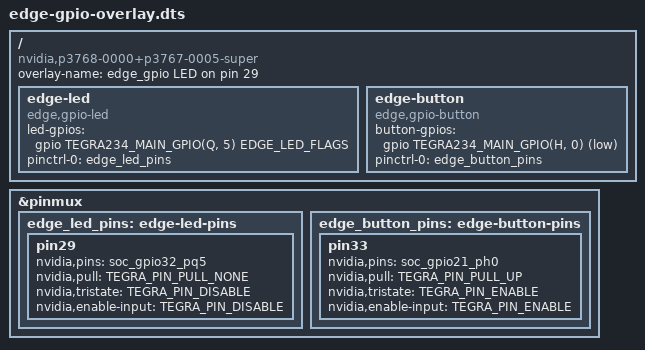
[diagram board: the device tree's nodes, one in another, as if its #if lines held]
// SPDX-License-Identifier: GPL-2.0
/*
 * Step 4: describe one LED on the 40-pin header so edge_gpio.ko can probe.
 *
 *   header pin 29 (GPIO01, SoC pad PQ.05) --[330R..1k]-->|-- pin 30 (GND)
 *
 * JP6 boots this pad tristated, so the node also carries a "default" pinctrl
 * state that turns the output buffer on; the platform core applies it right
 * before edge_gpio's probe().
 *
 * Built with cpp + dtc by dts/Makefile; -DEDGE_LED_ACTIVE_LOW builds the
 * variant for an LED wired from 3.3 V into the pin (lit when the pin is low).
 */
/dts-v1/;
/plugin/;

#include <dt-bindings/gpio/gpio.h>
#include <dt-bindings/gpio/tegra234-gpio.h>
#include <dt-bindings/pinctrl/pinctrl-tegra.h>

#ifdef EDGE_LED_ACTIVE_LOW
#define EDGE_LED_FLAGS GPIO_ACTIVE_LOW
#else
#define EDGE_LED_FLAGS GPIO_ACTIVE_HIGH
#endif

/ {
	overlay-name = "edge_gpio LED on pin 29";
	compatible = "nvidia,p3768-0000+p3767-0005-super", "nvidia,p3768-0000+p3767-0005";

	fragment@0 {
		target-path = "/";
		__overlay__ {
			edge-led {
				compatible = "edge,gpio-led";
				led-gpios = <&gpio TEGRA234_MAIN_GPIO(Q, 5) EDGE_LED_FLAGS>;
				pinctrl-names = "default";
				pinctrl-0 = <&edge_led_pins>;
			};
		};
	};

	fragment@1 {
		target = <&pinmux>;
		__overlay__ {
			edge_led_pins: edge-led-pins {
				pin29 {
					nvidia,pins = "soc_gpio32_pq5";
					nvidia,pull = <TEGRA_PIN_PULL_NONE>;
					nvidia,tristate = <TEGRA_PIN_DISABLE>;
					nvidia,enable-input = <TEGRA_PIN_DISABLE>;
				};
			};
		};
	};

	/*
	 * Step 5-b: push button for edge_button.ko.
	 *
	 *   pin 1 (3.3 V) --[330R]--+-- header pin 33 (GPIO13, SoC pad PH.00)
	 *                           +--[button]-- pin 34 (GND)
	 *
	 * Pressed pulls the pin low, hence GPIO_ACTIVE_LOW (logical 1 = pressed).
	 * The pad never drives (tristate) so a press can't short an output, and
	 * samples the pin (enable-input). The pull-up is the external resistor: on
	 * the devkit carrier pin 33 sits behind a TXB0108 level translator, whose
	 * ~4k buffers hold the last level, so the SoC pull-up below cannot lift the
	 * header pin (measured: reads 0 with nothing attached). It is kept only
	 * because it does no harm.
	 */
	fragment@2 {
		target-path = "/";
		__overlay__ {
			edge-button {
				compatible = "edge,gpio-button";
				button-gpios = <&gpio TEGRA234_MAIN_GPIO(H, 0) GPIO_ACTIVE_LOW>;
				pinctrl-names = "default";
				pinctrl-0 = <&edge_button_pins>;
			};
		};
	};

	fragment@3 {
		target = <&pinmux>;
		__overlay__ {
			edge_button_pins: edge-button-pins {
				pin33 {
					nvidia,pins = "soc_gpio21_ph0";
					nvidia,pull = <TEGRA_PIN_PULL_UP>;
					nvidia,tristate = <TEGRA_PIN_ENABLE>;
					nvidia,enable-input = <TEGRA_PIN_ENABLE>;
				};
			};
		};
	};
};
